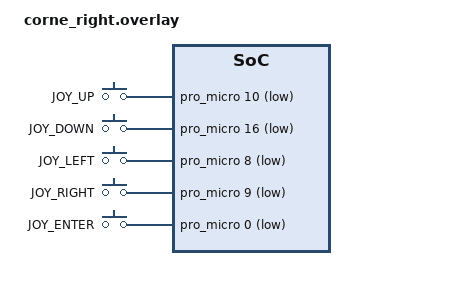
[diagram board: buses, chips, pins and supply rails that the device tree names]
/* config/corne_right.overlay */
#include <dt-bindings/zmk/matrix_transform.h>

/ {
    chosen {
        zmk,kscan = &kscan0;
    };

    /* Joystick (Pinos Livres: 10, 16, 8, 9, 0) */
    joystick_keys {
        compatible = "gpio-keys";
        
        joy_up: joy_up {
            label = "JOY_UP";
            gpios = <&pro_micro 10 (GPIO_ACTIVE_LOW | GPIO_PULL_UP)>;
            zephyr,code = <103>;
        };
        joy_down: joy_down {
            label = "JOY_DOWN";
            gpios = <&pro_micro 16 (GPIO_ACTIVE_LOW | GPIO_PULL_UP)>;
            zephyr,code = <108>;
        };
        joy_left: joy_left {
            label = "JOY_LEFT";
            gpios = <&pro_micro 8 (GPIO_ACTIVE_LOW | GPIO_PULL_UP)>;
            zephyr,code = <105>;
        };
        joy_right: joy_right {
            label = "JOY_RIGHT";
            gpios = <&pro_micro 9 (GPIO_ACTIVE_LOW | GPIO_PULL_UP)>;
            zephyr,code = <106>;
        };
        joy_center: joy_center {
            label = "JOY_ENTER";
            gpios = <&pro_micro 0 (GPIO_ACTIVE_LOW | GPIO_PULL_UP)>;
            zephyr,code = <28>;
        };
    };
};

/* --- MATRIZ DE TECLAS (PINAGEM DO CHINÊS) --- */
&kscan0 {
    row-gpios
        = <&pro_micro 4 (GPIO_ACTIVE_HIGH | GPIO_PULL_DOWN)>
        , <&pro_micro 5 (GPIO_ACTIVE_HIGH | GPIO_PULL_DOWN)>
        , <&pro_micro 6 (GPIO_ACTIVE_HIGH | GPIO_PULL_DOWN)>
        , <&pro_micro 7 (GPIO_ACTIVE_HIGH | GPIO_PULL_DOWN)>
        ;

    col-gpios
        = <&pro_micro 14 GPIO_ACTIVE_HIGH>
        , <&pro_micro 15 GPIO_ACTIVE_HIGH>
        , <&pro_micro 18 GPIO_ACTIVE_HIGH>
        , <&pro_micro 19 GPIO_ACTIVE_HIGH>
        , <&pro_micro 20 GPIO_ACTIVE_HIGH>
        , <&pro_micro 21 GPIO_ACTIVE_HIGH>
        ;
};
